# MPS2_SSE_200 register map
Vendor: ARM Ltd.; Series: ARMv8-M Mainline; File version: 1.0
CPU: CM33 r0p0, little endian, MPU, no FPU, 4 interrupt priority bits, 8 SAU regions
Registers are 32-bit, read-write, reset 0x0 unless marked. A register's access mark holds for its fields unless they carry their own. Offsets are from the block's base; [hi:lo] are bit positions; {n}, {i} and the like mark numbered series.

## SPCTRL — Secure Privilege Control Block
Base 0x50080000
0x00 SPCSECTRL — Secure Privilege Controller Secure Configuration Control register
0x04 BUSWAIT — Bus Access wait control after reset
0x10 SECRESPCFG — Security Violation Response Configuration register
0x14 NSCCFG — Non Secure Callable Configuration for IDAU
0x1C SECMPCINTSTATUS ro — Secure MPC Interrupt Status
0x20 SECPPCINTSTAT ro — Secure PPC Interrupt Status
0x24 SECPPCINTCLR wo — Secure PPC Interrupt Clear
0x28 SECPPCINTEN — Secure PPC Interrupt Enable
0x30 SECMSCINTSTAT ro — Secure MSC Interrupt Status
0x34 SECMSCINTCLR — Secure MSC Interrupt Clear
0x38 SECMSCINTEN — Secure MSC Interrupt Enable
0x40 BRGINTSTAT ro — Bridge Buffer Error Interrupt Status
0x44 BRGINTCLR wo — Bridge Buffer Error Interrupt Clear
0x48 BRGINTEN — Bridge Buffer Error Interrupt Enable
0x50 AHBNSPPC0 — Non-Secure Access AHB slave Peripheral Protection Control 0
{0x60+4i} AHBNSPPCEXP{i} (i=0..3) — Expansion {i} Non_Secure Access AHB slave Peripheral Protection Control
0x70 APBNSPPC0 — Non-Secure Access APB slave Peripheral Protection Control 0
0x74 APBNSPPC1 — Non-Secure Access APB slave Peripheral Protection Control 1
{0x80+4i} APBNSPPCEXP{i} (i=0..3) — Expansion {i} Non_Secure Access APB slave Peripheral Protection Control
0x90 AHBSPPPC0 ro — Secure Unprivileged Access AHB slave Peripheral Protection Control 0
{0xA0+4i} AHBSPPPCEXP{i} (i=0..3) — Expansion {i} Secure Unprivileged Access AHB slave Peripheral Protection Control
0xB0 APBSPPPC0 — Secure Unprivileged Access APB slave Peripheral Protection Control 0
0xB4 APBSPPPC1 — Secure Unprivileged Access APB slave Peripheral Protection Control 1
{0xC0+4i} APBSPPPCEXP{i} (i=0..3) — Expansion {i} Secure Unprivileged Access APB slave Peripheral Protection Control
0xD0 NSMSCEXP ro — Expansion MSC Non-Secure Configuration
0xFD0 PID4 ro reset 0x4 — Peripheral ID 4
0xFE0 PID0 ro reset 0x52 — Peripheral ID 0
0xFE4 PID1 ro reset 0xB8 — Peripheral ID 1
0xFE8 PID2 ro reset 0xB — Peripheral ID 2
0xFEC PID3 ro — Peripheral ID 3
0xFF0 CIDR0 ro reset 0xD — Component ID 0
0xFF4 CIDR1 ro reset 0xF0 — Component ID 1
0xFF8 CIDR2 ro reset 0x5 — Component ID 2
0xFFC CIDR3 ro reset 0xB1 — Component ID 3

## NSPCTRL — Non-secure Privilege Control Block
Base 0x40080000
0x90 AHBNSPPPC0 — Non-Secure Unprivileged Access AHB slave Peripheral Protection Control #0
{0xA0+4i} AHBNSPPPCEXP{i} (i=0..3) — Expansion {i} Non_Secure Unprivileged Access AHB slave Peripheral Protection Control
0xB0 APBNSPPPC0 — Non-Secure Unprivileged Access APB slave Peripheral Protection Control 0
0xB4 APBNSPPPC1 — Non-Secure Unprivileged Access APB slave Peripheral Protection Control 1
{0xC0+4i} APBNSPPPCEXP{i} (i=0..3) — Expansion {i} Non_Secure Unprivileged Access APB slave Peripheral Protection Control
0xFD0 PIDR4 ro — Peripheral ID 4
0xFE0 PIDR0 ro reset 0x53 — Peripheral ID 0
0xFE4 PIDR1 ro reset 0xB8 — Peripheral ID 1
0xFE8 PIDR2 ro reset 0xB — Peripheral ID 2
0xFEC PIDR3 ro — Peripheral ID 3
0xFF0 CIDR0 ro reset 0xD — Component ID 0
0xFF4 CIDR1 ro reset 0xF0 — Component ID 1
0xFF8 CIDR2 ro reset 0x5 — Component ID 2
0xFFC CIDR3 ro reset 0xB1 — Component ID 3

## SRAM0MPC — Memory Protection Controller 0
Base 0x50083000
Same registers: SRAM1MPC 0x50084000, SRAM2MPC 0x50085000, SRAM3MPC 0x50086000, SSRAM1MPC 0x58007000, SSRAM2MPC 0x58008000, SSRAM3MPC 0x58009000
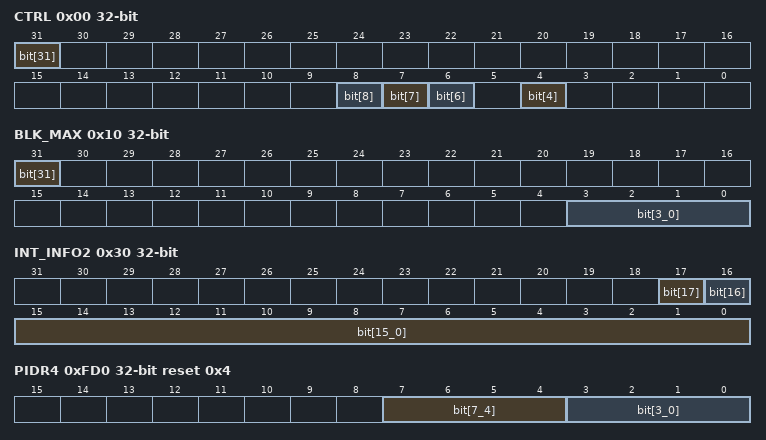
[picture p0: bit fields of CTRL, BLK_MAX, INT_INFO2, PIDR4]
0x00 CTRL — MPC Control register
  [31] bit[31] — Security lockdown
  [8] bit[8] — Auto-increment
  [7] bit[7] — Data interface gating acknowledge (RO)
  [6] bit[6] — Data interface gating request
  [4] bit[4] — Security error response configuration
    0=RAZ-WI (Read-As-Zero - Writes ignored); 1=BUSERROR
0x10 BLK_MAX ro — Maximum value of block based index register
  [31] bit[31] — Initialization in progress
  [3:0] bit[3_0] — Block size
0x14 BLK_CFG ro — Block Configuration
0x18 BLK_IDX — Index value for accessing block based look up table
0x1C BLK_LUT — Block based gating Look Up Table
0x20 INT_STAT ro — Interrupt state
  [0] bit[0] — mpc_irq triggered
0x24 INT_CLEAR wo — Interrupt clear
  [0] bit[0] — mpc_irq clear (cleared automatically)
0x28 INT_EN — Interrupt enable
  [0] bit[0] — mpc_irq enable. Bits are valid when mpc_irq triggered is set
0x2C INT_INFO1 ro — Interrupt information 1
0x30 INT_INFO2 ro — Interrupt information 2
  [17] bit[17] — cfg_ns
  [16] bit[16] — hnonsec
  [15:0] bit[15_0] — hmaster
0x34 INT_SET wo — Interrupt set. Debug purpose only
  [0] bit[0] — mpc_irq set. Debug purpose only
0xFD0 PIDR4 ro reset 0x4 — Peripheral ID 4
  [7:4] bit[7_4] — block count
  [3:0] bit[3_0] — jep106_c_code
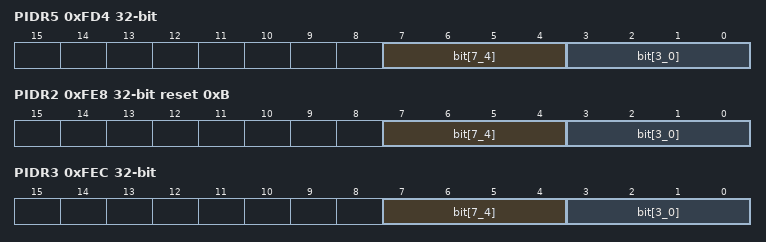
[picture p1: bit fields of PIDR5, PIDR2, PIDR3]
0xFD4 PIDR5 ro — Peripheral ID 5
  [7:4] bit[7_4] — jep106_id_3_0
  [3:0] bit[3_0] — Part number
0xFD8 PIDR6 ro — Peripheral ID 6
0xFDC PIDR7 ro — Peripheral ID 7
0xFE0 PIDR0 ro reset 0x60 — Peripheral ID 0
0xFE4 PIDR1 ro reset 0xB8 — Peripheral ID 1
0xFE8 PIDR2 ro reset 0xB — Peripheral ID 2
  [7:4] bit[7_4] — jep106_id_3_0
  [3:0] bit[3_0] — Part number
0xFEC PIDR3 ro — Peripheral ID 3
  [7:4] bit[7_4] — ECO revision number
  [3:0] bit[3_0] — Customer modification number
0xFF0 CIDR0 ro reset 0xD — Component ID 0
0xFF4 CIDR1 ro reset 0xF0 — Component ID 1
0xFF8 CIDR2 ro reset 0x5 — Component ID 2
0xFFC CIDR3 ro reset 0xB1 — Component ID 3
